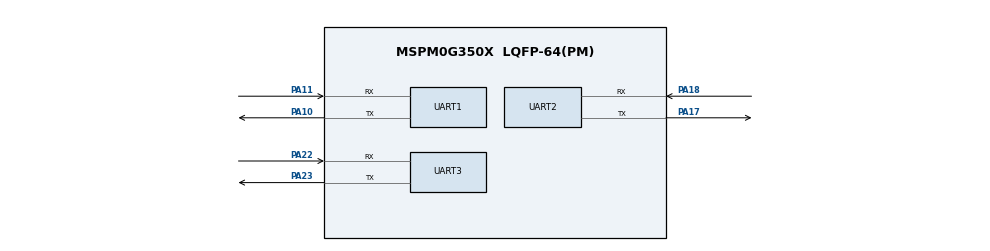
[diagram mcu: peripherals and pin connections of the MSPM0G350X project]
/**
 * @cliArgs --device "MSPM0G350X" --part "Default" --package "LQFP-64(PM)" --product "mspm0_sdk@2.10.00.04"
 * @versions {"tool":"1.26.2+4477"}
 */

/**
 * Import the modules used in this configuration.
 */
const GPIO          = scripting.addModule("/ti/driverlib/GPIO", {}, false);
const GPIO1         = GPIO.addInstance();
const SYSCTL        = scripting.addModule("/ti/driverlib/SYSCTL");
const UART          = scripting.addModule("/ti/driverlib/UART", {}, false);
const UART1         = UART.addInstance();
const UART2         = UART.addInstance();
const UART3         = UART.addInstance();
const ProjectConfig = scripting.addModule("/ti/project_config/ProjectConfig");

/**
 * Write custom configuration values to the imported modules.
 */
GPIO1.$name                          = "LED1";
GPIO1.associatedPins[0].$name        = "PIN_14";
GPIO1.associatedPins[0].assignedPort = "PORTA";
GPIO1.associatedPins[0].assignedPin  = "14";

const Board = scripting.addModule("/ti/driverlib/Board", {}, false);

SYSCTL.clockTreeEn = true;

UART1.$name                    = "UART_0";
UART1.targetBaudRate           = 115200;
UART1.peripheral.rxPin.$assign = "PA11";
UART1.peripheral.txPin.$assign = "PA10";
UART1.txPinConfig.$name        = "ti_driverlib_gpio_GPIOPinGeneric0";
UART1.rxPinConfig.$name        = "ti_driverlib_gpio_GPIOPinGeneric1";

UART2.$name                    = "UART_1";
UART2.targetBaudRate           = 115200;
UART2.peripheral.$assign       = "UART1";
UART2.peripheral.rxPin.$assign = "PA18";
UART2.peripheral.txPin.$assign = "PA17";
UART2.txPinConfig.$name        = "ti_driverlib_gpio_GPIOPinGeneric2";
UART2.rxPinConfig.$name        = "ti_driverlib_gpio_GPIOPinGeneric3";

UART3.$name                    = "UART_2";
UART3.targetBaudRate           = 115200;
UART3.peripheral.$assign       = "UART2";
UART3.peripheral.rxPin.$assign = "PA22";
UART3.peripheral.txPin.$assign = "PA23";
UART3.txPinConfig.$name        = "ti_driverlib_gpio_GPIOPinGeneric4";
UART3.rxPinConfig.$name        = "ti_driverlib_gpio_GPIOPinGeneric5";

ProjectConfig.genDisable = true;

/**
 * Pinmux solution for unlocked pins/peripherals. This ensures that minor changes to the automatic solver in a future
 * version of the tool will not impact the pinmux you originally saw.  These lines can be completely deleted in order to
 * re-solve from scratch.
 */
GPIO1.associatedPins[0].pin.$suggestSolution = "PA14";
Board.peripheral.$suggestSolution            = "DEBUGSS";
Board.peripheral.swclkPin.$suggestSolution   = "PA20";
Board.peripheral.swdioPin.$suggestSolution   = "PA19";
UART1.peripheral.$suggestSolution            = "UART0";
